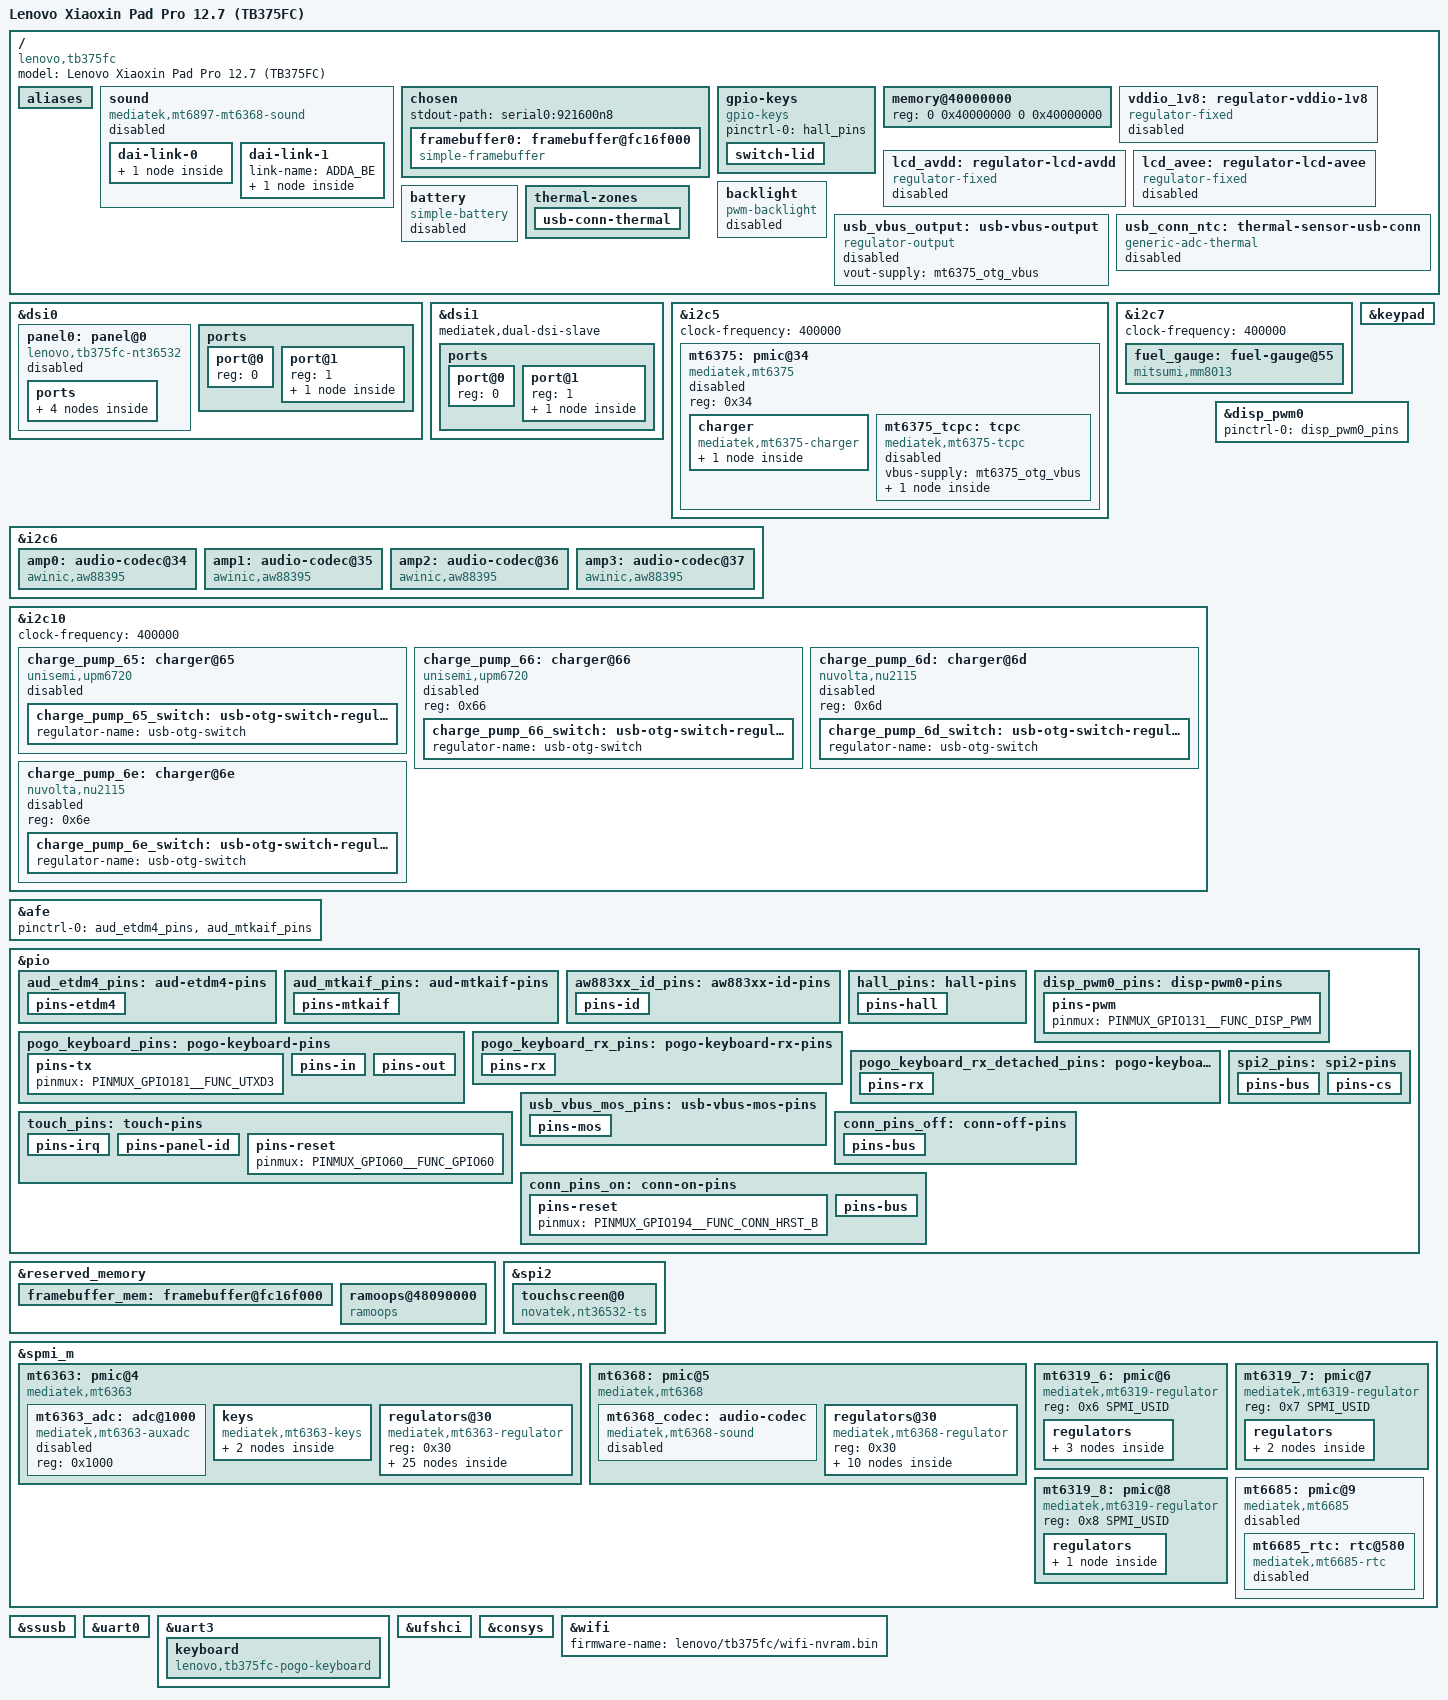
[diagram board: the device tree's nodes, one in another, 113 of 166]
// SPDX-License-Identifier: (GPL-2.0-only OR BSD-2-Clause)
/*
 * Lenovo Xiaoxin Pad Pro 12.7 (2025, TB375FC)
 *
 * Copyright (c) 2026 buntOS contributors
 */

/dts-v1/;
#include <dt-bindings/gpio/gpio.h>
#include <dt-bindings/iio/adc/mediatek,mt6363-auxadc.h>
#include <dt-bindings/input/gpio-keys.h>
#include <dt-bindings/input/input.h>
#include <dt-bindings/interrupt-controller/irq.h>
#include <dt-bindings/spmi/spmi.h>
#include <dt-bindings/usb/pd.h>
#include "mt6897.dtsi"
#include "mt6897-pinfunc.h"

/ {
	model = "Lenovo Xiaoxin Pad Pro 12.7 (TB375FC)";
	compatible = "lenovo,tb375fc", "mediatek,mt6897";

	aliases {
		i2c5 = &i2c5;
		i2c10 = &i2c10;
		serial0 = &uart0;
		spmi0 = &spmi_m;
	};

	sound: sound {
		compatible = "mediatek,mt6897-mt6368-sound";
		model = "TB375FC";
		mediatek,platform = <&afe>;
		audio-routing =
			"Speakers", "Amp0 DAC Output",
			"Speakers", "Amp1 DAC Output",
			"Speakers", "Amp2 DAC Output",
			"Speakers", "Amp3 DAC Output";
		status = "disabled";

		dai-link-0 {
			link-name = "I2SOUT4_BE";
			dai-format = "dsp_b";
			mediatek,clk-provider = "cpu";

			codec {
				sound-dai = <&amp0>, <&amp1>, <&amp2>, <&amp3>;
			};
		};

		dai-link-1 {
			link-name = "ADDA_BE";

			codec {
				sound-dai = <&mt6368_codec>;
			};
		};
	};

	chosen {
		#address-cells = <2>;
		#size-cells = <2>;
		ranges;

		stdout-path = "serial0:921600n8";

		/*
		 * The bootloader drives the panel over both DSI links with DSC
		 * and scans out one 2944x1840 buffer. The base is the one in the
		 * tree it passes to the vendor kernel (atag,videolfb). The stride
		 * and format are from the community port.
		 */
		framebuffer0: framebuffer@fc16f000 {
			compatible = "simple-framebuffer";
			reg = <0 0xfc16f000 0 (2944 * 1840 * 4)>;
			width = <2944>;
			height = <1840>;
			stride = <(2944 * 4)>;
			format = "a8r8g8b8";
			panel = <&panel0>;
		};
	};

	/*
	 * Hall sensor. GPIO1 (stock hall_1) goes low when the cover closes
	 * over the screen. The stock hall_2 is the keyboard's plug-gpios, under
	 * &uart3. The tablet has no sensor for the keyboard folded back: the
	 * keyboard reports that itself, and its driver turns it into
	 * SW_TABLET_MODE.
	 * Checked on the device: low while a cover is closed. Only opening
	 * wakes the tablet: closing a cover over a sleeping tablet woke it,
	 * and logind ignores the lid for a while after a wakeup, so the
	 * screen stayed on under the cover.
	 */
	gpio-keys {
		compatible = "gpio-keys";
		pinctrl-names = "default";
		pinctrl-0 = <&hall_pins>;

		switch-lid {
			label = "Lid";
			gpios = <&pio 1 GPIO_ACTIVE_LOW>;
			linux,input-type = <EV_SW>;
			linux,code = <SW_LID>;
			debounce-interval = <100>;
			wakeup-source;
			wakeup-event-action = <EV_ACT_DEASSERTED>;
		};
	};

	memory@40000000 {
		device_type = "memory";
		/* The bootloader fills in the real size (8 or 12 GiB) */
		reg = <0 0x40000000 0 0x40000000>;
	};

	/*
	 * The panel's 1.8 V I/O supply behind a switch on GPIO63 (stock
	 * vddio_1v8-gpios), which the touch side of the NT36532 shares. The
	 * bootloader turns it on with the panel, and nothing may turn it off
	 * while the display runs on simple-framebuffer. It stays on with the panel
	 * driver: stock turns it on before the DSI links and off after them, which
	 * the driver cannot do, and turns it on before it reads the panel ID strap.
	 * TODO(2c): enable with pio.
	 */
	vddio_1v8: regulator-vddio-1v8 {
		compatible = "regulator-fixed";
		regulator-name = "vddio_1v8";
		regulator-min-microvolt = <1800000>;
		regulator-max-microvolt = <1800000>;
		gpio = <&pio 63 GPIO_ACTIVE_HIGH>;
		enable-active-high;
		regulator-boot-on;
		regulator-always-on;
		status = "disabled";
	};

	/*
	 * The enables of the panel's bias chip, an SM5109 at 0x3e on i2c13 (stock
	 * bias_p-gpios and bias_n-gpios). The bootloader turns them on and writes
	 * 0x12 to its two voltage registers, and the stock kernel does too. Stock
	 * also waits 80 ms after the panel goes off. The chip does not keep the
	 * voltages while off: it reads 0x0e after the panel comes back. TODO: write
	 * them again at every power on. 5.8 V is the value by the formula of the
	 * TPS65132, which has the same two registers; the SM5109's is not known.
	 */
	lcd_avdd: regulator-lcd-avdd {
		compatible = "regulator-fixed";
		regulator-name = "lcd_avdd";
		regulator-min-microvolt = <5800000>;
		regulator-max-microvolt = <5800000>;
		gpio = <&pio 187 GPIO_ACTIVE_HIGH>;
		enable-active-high;
		regulator-boot-on;
		off-on-delay-us = <80000>;
		status = "disabled";
	};

	lcd_avee: regulator-lcd-avee {
		compatible = "regulator-fixed";
		regulator-name = "lcd_avee";
		regulator-min-microvolt = <5800000>;
		regulator-max-microvolt = <5800000>;
		gpio = <&pio 186 GPIO_ACTIVE_HIGH>;
		enable-active-high;
		regulator-boot-on;
		off-on-delay-us = <80000>;
		status = "disabled";
	};

	/*
	 * The display PWM of the SoC sets the brightness, as in the stock tree
	 * (mtk-leds, led-mode 5) and the bootloader's log. Its one output dims the
	 * two SGM37604A LED drivers together, at 0x36 on i2c13 and i2c3. The panel
	 * does nothing with DCS 0x51. The bootloader sets up both LED drivers:
	 * current = I2C code x PWM, with their ramp on, and code 0xdb6, which makes
	 * 21.4 mA per string at full duty. They keep it, so they need no driver.
	 *
	 * The period is the one of the stock tree and of the bootloader, which runs
	 * the PWM at 104 MHz. The LED drivers take 20 to 100 kHz. The levels are
	 * percent of lightness by CIE 1931, as in the default table of pwm-backlight.
	 * Level 1 is about the stock minimum of 4, and the default about the
	 * bootloader's 1945.
	 */
	backlight: backlight {
		compatible = "pwm-backlight";
		pwms = <&disp_pwm0 0 39380>;
		brightness-levels = <0 5 9 14 18 23 27 32 36 41
				     46 52 58 64 71 78 86 94 103 112
				     122 133 144 156 168 181 194 209 223 239
				     255 272 290 309 328 348 369 391 413 436
				     461 486 512 539 567 595 625 656 688 720
				     754 789 825 862 900 939 979 1021 1063 1107
				     1152 1198 1245 1293 1343 1394 1447 1500 1555 1611
				     1669 1728 1788 1849 1913 1977 2043 2110 2179 2249
				     2321 2394 2469 2546 2623 2703 2784 2867 2951 3037
				     3125 3214 3305 3397 3492 3588 3686 3785 3887 3990
				     4095>;
		default-brightness-level = <75>;
		status = "disabled";
	};

	/*
	 * Charging through the MT6375, with the values of the stock tree: ieoc,
	 * min-charge-temp, max-charge-temp, and a charge current of 3 A
	 * (sc-charger-current, and what stock takes from a 3 A Type-C current or a
	 * 5 V PD contract). The voltage is the lowest of its battery maintenance
	 * table, which a battery of any age can take (maintenance-v20-level0-cv,
	 * maintenance-v10-level3-cv), not the 4.5 V of battery-cv. Stock has no
	 * over-voltage threshold of its own, so that one is the next step up in the
	 * fuel gauge's column of that table (maintenance-v10-level2-fg-cv). The
	 * charge pump charges faster with the direct_charge parameter of the charger
	 * driver, which is off by default.
	 */
	battery: battery {
		compatible = "simple-battery";
		constant-charge-voltage-max-microvolt = <4340000>;
		constant-charge-current-max-microamp = <3000000>;
		charge-term-current-microamp = <350000>;
		over-voltage-threshold-microvolt = <4410000>;
		operating-range-celsius = <0 50>;
		status = "disabled";
	};

	/*
	 * Turns the USB VBUS boost on and off from user space, through the state
	 * attribute of this device, until the TCPC driver takes that over. Stays
	 * off with the MT6375 (see &i2c5).
	 */
	usb_vbus_output: usb-vbus-output {
		compatible = "regulator-output";
		vout-supply = <&mt6375_otg_vbus>;
		status = "disabled";
	};

	/*
	 * The NTC at the USB connector, on VIN4 of the MT6363 with its 100 kOhm
	 * pull-up (stock usb_board_ntc on vin4-100k). The resistances are the
	 * ones of the stock table. The AUXADC driver hands out the reading times
	 * its full scale, so a value here is 32768 * R / (R + 100000) * 1840.
	 * Steps of one degree also keep the interpolation in the driver in range.
	 */
	usb_conn_ntc: thermal-sensor-usb-conn {
		compatible = "generic-adc-thermal";
		#thermal-sensor-cells = <0>;
		io-channels = <&mt6363_adc MT6363_AUXADC_VIN4>;
		io-channel-names = "sensor-channel";
		temperature-lookup-table = <
			(-40000) 58951760
			(-39000) 58854240
			(-38000) 58751200
			(-37000) 58640800
			(-36000) 58524880
			(-35000) 58401600
			(-34000) 58270960
			(-33000) 58132960
			(-32000) 57985760
			(-31000) 57831200
			(-30000) 57667440
			(-29000) 57494480
			(-28000) 57312320
			(-27000) 57120960
			(-26000) 56920400
			(-25000) 56706960
			(-24000) 56484320
			(-23000) 56248800
			(-22000) 56002240
			(-21000) 55742800
			(-20000) 55472320
			(-19000) 55188960
			(-18000) 54892720
			(-17000) 54583600
			(-16000) 54259760
			(-15000) 53923040
			(-14000) 53571600
			(-13000) 53205440
			(-12000) 52826400
			(-11000) 52430800
			(-10000) 52022320
			(-9000) 51595440
			(-8000) 51155680
			(-7000) 50701200
			(-6000) 50230160
			(-5000) 49744400
			(-4000) 49245760
			(-3000) 48730560
			(-2000) 48200640
			(-1000) 47657840
			0 47098480
			1000 46526240
			2000 45941120
			3000 45341280
			4000 44730400
			5000 44106640
			6000 43470000
			7000 42824160
			8000 42167280
			9000 41501200
			10000 40824080
			11000 40139600
			12000 39449600
			13000 38750400
			14000 38045680
			15000 37337280
			16000 36621520
			17000 35905760
			18000 35184480
			19000 34463200
			20000 33740080
			21000 33018800
			22000 32297520
			23000 31576240
			24000 30860480
			25000 30146560
			26000 29436320
			27000 28729760
			28000 28030560
			29000 27336880
			30000 26650560
			31000 25971600
			32000 25300000
			33000 24637600
			34000 23984400
			35000 23340400
			36000 22705600
			37000 22083680
			38000 21470960
			39000 20867440
			40000 20276800
			41000 19699040
			42000 19132320
			43000 18576640
			44000 18033840
			45000 17502080
			46000 16981360
			47000 16475360
			48000 15980400
			49000 15496480
			50000 15025440
			51000 14567280
			52000 14120160
			53000 13685920
			54000 13262720
			55000 12850560
			56000 12451280
			57000 12063040
			58000 11685840
			59000 11317840
			60000 10962720
			61000 10616800
			62000 10281920
			63000 9956240
			64000 9641600
			65000 9336160
			66000 9039920
			67000 8752880
			68000 8476880
			69000 8206400
			70000 7946960
			71000 7694880
			72000 7450160
			73000 7212800
			74000 6984640
			75000 6762000
			76000 6548560
			77000 6340640
			78000 6141920
			79000 5946880
			80000 5761040
			81000 5578880
			82000 5404080
			83000 5234800
			84000 5071040
			85000 4912800
			86000 4760080
			87000 4611040
			88000 4467520
			89000 4329520
			90000 4195200
			91000 4066400
			92000 3941280
			93000 3821680
			94000 3703920
			95000 3591680
			96000 3483120
			97000 3376400
			98000 3273360
			99000 3175840
			100000 3080160
			101000 2986320
			102000 2898000
			103000 2811520
			104000 2728720
			105000 2647760
			106000 2568640
			107000 2493200
			108000 2419600
			109000 2349680
			110000 2281600
			111000 2215360
			112000 2150960
			113000 2088400
			114000 2029520
			115000 1970640
			116000 1913600
			117000 1860240
			118000 1808720
			119000 1757200
			120000 1707520
			121000 1659680
			122000 1613680
			123000 1567680
			124000 1525360
			125000 1483040
		>;
		status = "disabled";
	};

	thermal-zones {
		/* The charger reads this one, at its own pace */
		usb-conn-thermal {
			polling-delay = <0>;
			polling-delay-passive = <0>;
			thermal-sensors = <&usb_conn_ntc>;
		};
	};
};

/*
 * The tablet ships with one of three panels. The driver tells BOE from Tianma
 * by the strap on GPIO184, which the touchscreen reads as well; the two Tianma
 * panels take the same init sequence.
 *
 * The stock bootloader does not need these nodes to turn the display on, it has
 * its own device tree for that. On the way to the kernel it looks for
 * /soc/dsi/panel<n>/port/endpoint and logs a failure when it is not there.
 *
 * TODO(2c display): enable with the display pipeline, and take the panel
 * property off framebuffer0 at the same time: fw_devlink would hold simpledrm
 * back until the panel binds. Until then the display runs on simple-framebuffer.
 * The two links make one panel: dsi1 only follows dsi0.
 */
&dsi0 {
	panel0: panel@0 {
		compatible = "lenovo,tb375fc-nt36532", "novatek,nt36532";
		reg = <0>;
		width-mm = <273>;
		height-mm = <171>;
		reset-gpios = <&pio 41 GPIO_ACTIVE_LOW>;
		novatek,panel-id-gpios = <&pio 184 GPIO_ACTIVE_HIGH>;
		vddio-supply = <&vddio_1v8>;
		avdd-supply = <&lcd_avdd>;
		avee-supply = <&lcd_avee>;
		backlight = <&backlight>;
		status = "disabled";

		ports {
			#address-cells = <1>;
			#size-cells = <0>;

			port@0 {
				reg = <0>;

				panel_in0: endpoint {
					remote-endpoint = <&dsi0_out>;
				};
			};

			port@1 {
				reg = <1>;

				panel_in1: endpoint {
					remote-endpoint = <&dsi1_out>;
				};
			};
		};
	};

	ports {
		#address-cells = <1>;
		#size-cells = <0>;

		port@0 {
			reg = <0>;
		};

		port@1 {
			reg = <1>;

			dsi0_out: endpoint {
				remote-endpoint = <&panel_in0>;
			};
		};
	};
};

&dsi1 {
	mediatek,dual-dsi-slave;

	ports {
		#address-cells = <1>;
		#size-cells = <0>;

		port@0 {
			reg = <0>;
		};

		port@1 {
			reg = <1>;

			dsi1_out: endpoint {
				remote-endpoint = <&panel_in1>;
			};
		};
	};
};

/*
 * The MT6375 sources VBUS for USB host mode. Its boost feeds the connector
 * through the input FETs of the charge pump below, which stock closes first.
 *
 * TODO(USB host): stays off with &usb_vbus_output, &i2c5, &i2c10 and
 * &imp_iic_wrap_n/en until UFS root and the USB gadget work on the device. It
 * also needs &pio for its GPIO179 state. The stock tree has no pins and no pull
 * setting for these buses, and runs them at 1 MHz. Check with i2cdetect first,
 * reading only.
 *
 * TODO(charging): with this node alone the driver only reads and charging stays
 * as the bootloader set it. Add monitored-battery = <&battery> and
 * mediatek,fuel-gauge to the charger for it to take over, once the gauge works.
 *
 * TODO(TCPC): add interrupt-parent = <&pio> and interrupts = <7 IRQ_TYPE_LEVEL_LOW>
 * here, which masks all interrupts of the chip at probe, and enable &mt6375_tcpc.
 * First as below, then with power-role and data-role dual (and try-power-role
 * sink), mediatek,usb-port in the charger, &usb_vbus_output off and the port of
 * &ssusb. The order is in the bring-up checklist.
 */
&i2c5 {
	clock-frequency = <400000>;

	mt6375: pmic@34 {
		compatible = "mediatek,mt6375";
		reg = <0x34>;
		status = "disabled";

		charger {
			compatible = "mediatek,mt6375-charger";
			pinctrl-names = "default";
			pinctrl-0 = <&usb_vbus_mos_pins>;
			mediatek,charge-pump = <&charge_pump_65>;

			mt6375_otg_vbus: usb-otg-vbus-regulator {
				regulator-name = "usb-otg-vbus";
				regulator-min-microvolt = <5000000>;
				regulator-max-microvolt = <5000000>;
				vbus-switch-supply = <&charge_pump_65_switch>;
			};
		};

		/*
		 * The fixed contracts that stock takes through the MT6375: 5 V 3 A and
		 * 9 V 2 A. The 9 V line needs the limits that the charge pump driver
		 * writes at probe, as the chip resets to an input over-voltage of 6.5 V,
		 * so that driver loads before this one. op-sink-microwatt stays low as
		 * TCPM cannot ask a PPS source for less. A hard reset, from the source
		 * or after a failed negotiation, takes VBUS away from the USB gadget.
		 * USB 3 may not work until there is a driver for the PS5170 redriver,
		 * which stock sets up by the orientation that the TCPC reports.
		 */
		mt6375_tcpc: tcpc {
			compatible = "mediatek,mt6375-tcpc";
			vbus-supply = <&mt6375_otg_vbus>;
			status = "disabled";

			connector {
				compatible = "usb-c-connector";
				label = "USB-C";
				data-role = "device";
				power-role = "sink";
				sink-pdos = <PDO_FIXED(5000, 3000, PDO_FIXED_USB_COMM)
					     PDO_FIXED(9000, 2000, 0)>;
				op-sink-microwatt = <2500000>;
			};
		};
	};
};

/*
 * The stock tree lists all of these and its drivers bind what answers: NU2115 at
 * 0x6d and 0x6e, or UPM6720 at 0x65 and 0x66. The one that stock names
 * primary_dvchg closes the FETs: the master at 0x6d or 0x65, or a chip strapped
 * as standalone. On the one tablet read so far, stock binds only the UPM6720 at
 * 0x65, so vbus-switch-supply above points at it. Other units may differ.
 *
 * TODO(USB host): on the device, see with i2cdetect which ones answer and which
 * is not strapped as a slave, and enable that one only.
 */
/*
 * The four speakers' smart amplifiers, AW88394 by their stock tuning files. Each
 * takes one slot of the TDM link, which the file picks by audio-channel. The
 * GPIO82 strap tells who made the speakers, and the bus holds its pull-up so
 * that the strap reads true for whichever amplifier probes first. The driver
 * holds a reset line at 0 to reset the chip, so the lines are active high here.
 */
&i2c6 {
	clock-frequency = <400000>;
	pinctrl-names = "default";
	pinctrl-0 = <&aw883xx_id_pins>;

	amp0: audio-codec@34 {
		compatible = "awinic,aw88395";
		reg = <0x34>;
		#sound-dai-cells = <0>;
		reset-gpios = <&pio 78 GPIO_ACTIVE_HIGH>;
		firmware-name = "lenovo/tb375fc/aw883xx_acf_gyt.bin",
				"lenovo/tb375fc/aw883xx_acf_yc.bin";
		awinic,calibration-required;
		awinic,speaker-id-gpios = <&pio 82 GPIO_ACTIVE_HIGH>;
		awinic,audio-channel = <0>;
		sound-name-prefix = "Amp0";
	};

	amp1: audio-codec@35 {
		compatible = "awinic,aw88395";
		reg = <0x35>;
		#sound-dai-cells = <0>;
		reset-gpios = <&pio 79 GPIO_ACTIVE_HIGH>;
		firmware-name = "lenovo/tb375fc/aw883xx_acf_gyt.bin",
				"lenovo/tb375fc/aw883xx_acf_yc.bin";
		awinic,calibration-required;
		awinic,speaker-id-gpios = <&pio 82 GPIO_ACTIVE_HIGH>;
		awinic,audio-channel = <1>;
		sound-name-prefix = "Amp1";
	};

	amp2: audio-codec@36 {
		compatible = "awinic,aw88395";
		reg = <0x36>;
		#sound-dai-cells = <0>;
		reset-gpios = <&pio 80 GPIO_ACTIVE_HIGH>;
		firmware-name = "lenovo/tb375fc/aw883xx_acf_gyt.bin",
				"lenovo/tb375fc/aw883xx_acf_yc.bin";
		awinic,calibration-required;
		awinic,speaker-id-gpios = <&pio 82 GPIO_ACTIVE_HIGH>;
		awinic,audio-channel = <2>;
		sound-name-prefix = "Amp2";
	};

	amp3: audio-codec@37 {
		compatible = "awinic,aw88395";
		reg = <0x37>;
		#sound-dai-cells = <0>;
		reset-gpios = <&pio 81 GPIO_ACTIVE_HIGH>;
		firmware-name = "lenovo/tb375fc/aw883xx_acf_gyt.bin",
				"lenovo/tb375fc/aw883xx_acf_yc.bin";
		awinic,calibration-required;
		awinic,speaker-id-gpios = <&pio 82 GPIO_ACTIVE_HIGH>;
		awinic,audio-channel = <3>;
		sound-name-prefix = "Amp3";
	};
};

&i2c7 {
	clock-frequency = <400000>;

	fuel_gauge: fuel-gauge@55 {
		compatible = "mitsumi,mm8013";
		reg = <0x55>;
		/*
		 * The charger stops at the 4.34 V of &battery, not at the 4.5 V
		 * of stock that the model in the gauge presumably goes up to.
		 * The one full charge watched ended at 89 %, and it read 90 %
		 * hours later on the charger. One under the lower reading, so
		 * that a charge ending a little lower still reads 100 %.
		 */
		mitsumi,charged-soc-percent = <88>;
	};
};

&i2c10 {
	clock-frequency = <400000>;

	charge_pump_65: charger@65 {
		compatible = "unisemi,upm6720";
		reg = <0x65>;
		unisemi,usb-port = <&mt6375_tcpc>;
		unisemi,fuel-gauge = <&fuel_gauge>;
		status = "disabled";

		charge_pump_65_switch: usb-otg-switch-regulator {
			regulator-name = "usb-otg-switch";
		};
	};

	charge_pump_66: charger@66 {
		compatible = "unisemi,upm6720";
		reg = <0x66>;
		status = "disabled";

		charge_pump_66_switch: usb-otg-switch-regulator {
			regulator-name = "usb-otg-switch";
		};
	};

	charge_pump_6d: charger@6d {
		compatible = "nuvolta,nu2115";
		reg = <0x6d>;
		status = "disabled";

		charge_pump_6d_switch: usb-otg-switch-regulator {
			regulator-name = "usb-otg-switch";
		};
	};

	charge_pump_6e: charger@6e {
		compatible = "nuvolta,nu2115";
		reg = <0x6e>;
		status = "disabled";

		charge_pump_6e_switch: usb-otg-switch-regulator {
			regulator-name = "usb-otg-switch";
		};
	};
};

&keypad {
	/* The stock tree maps key 0 to volume down and debounces for 1024 ticks */
	keypad,num-rows = <1>;
	keypad,num-columns = <1>;
	linux,keymap = <MATRIX_KEY(0, 0, KEY_VOLUMEDOWN)>;
	debounce-delay-ms = <32>;
};

&disp_pwm0 {
	pinctrl-names = "default";
	pinctrl-0 = <&disp_pwm0_pins>;
};

&afe {
	pinctrl-names = "default";
	pinctrl-0 = <&aud_etdm4_pins>, <&aud_mtkaif_pins>;
};

&pio {
	aud_etdm4_pins: aud-etdm4-pins {
		pins-etdm4 {
			pinmux = <PINMUX_GPIO65__FUNC_I2SIN4_BCK>,
				 <PINMUX_GPIO4__FUNC_I2SIN4_LRCK>,
				 <PINMUX_GPIO5__FUNC_I2SIN4_DATA0>,
				 <PINMUX_GPIO62__FUNC_I2SOUT4_DATA0>;
			drive-strength = <6>;
			input-schmitt-enable;
			bias-disable;
		};
	};

	aud_mtkaif_pins: aud-mtkaif-pins {
		pins-mtkaif {
			pinmux = <PINMUX_GPIO222__FUNC_AUD_CLK_MOSI>,
				 <PINMUX_GPIO223__FUNC_AUD_SYNC_MOSI>,
				 <PINMUX_GPIO224__FUNC_AUD_DAT_MOSI0>,
				 <PINMUX_GPIO225__FUNC_AUD_DAT_MOSI1>,
				 <PINMUX_GPIO229__FUNC_AUD_DAT_MISO0>,
				 <PINMUX_GPIO230__FUNC_AUD_DAT_MISO1>,
				 <PINMUX_GPIO231__FUNC_AUD_DAT_MISO2>;
			input-schmitt-enable;
			bias-disable;
		};
	};

	aw883xx_id_pins: aw883xx-id-pins {
		pins-id {
			pinmux = <PINMUX_GPIO82__FUNC_GPIO82>;
			input-enable;
			bias-pull-up = <MTK_PUPD_SET_R1R0_10>;
		};
	};

	hall_pins: hall-pins {
		pins-hall {
			pinmux = <PINMUX_GPIO1__FUNC_GPIO1>;
			input-enable;
		};
	};

	disp_pwm0_pins: disp-pwm0-pins {
		pins-pwm {
			pinmux = <PINMUX_GPIO131__FUNC_DISP_PWM>;
		};
	};

	/*
	 * The keyboard cover has one data wire on its pogo pins. UART3 TX drives
	 * it through a gate on GPIO71, and UART3 RX and GPIO40 listen to it.
	 * The stock driver leaves TX on the UART and bias on GPIO26 and GPIO40
	 * as the bootloader set it.
	 */
	pogo_keyboard_pins: pogo-keyboard-pins {
		pins-tx {
			pinmux = <PINMUX_GPIO181__FUNC_UTXD3>;
		};

		pins-in {
			pinmux = <PINMUX_GPIO26__FUNC_GPIO26>,
				 <PINMUX_GPIO40__FUNC_GPIO40>;
			input-enable;
		};

		pins-out {
			pinmux = <PINMUX_GPIO61__FUNC_GPIO61>,
				 <PINMUX_GPIO71__FUNC_GPIO71>;
		};
	};

	pogo_keyboard_rx_pins: pogo-keyboard-rx-pins {
		pins-rx {
			pinmux = <PINMUX_GPIO180__FUNC_URXD3>;
			input-enable;
		};
	};

	/* Nothing drives the wire without a keyboard, so RX leaves the UART */
	pogo_keyboard_rx_detached_pins: pogo-keyboard-rx-detached-pins {
		pins-rx {
			pinmux = <PINMUX_GPIO180__FUNC_GPIO180>;
			input-enable;
			bias-disable;
		};
	};

	/* The stock tree sets drive strength 2, which is 6 mA */
	spi2_pins: spi2-pins {
		pins-bus {
			pinmux = <PINMUX_GPIO11__FUNC_SPI2_CLK>,
				 <PINMUX_GPIO13__FUNC_SPI2_MI>,
				 <PINMUX_GPIO14__FUNC_SPI2_MO>;
			drive-strength = <6>;
		};

		pins-cs {
			pinmux = <PINMUX_GPIO12__FUNC_GPIO12>;
			drive-strength = <6>;
		};
	};

	touch_pins: touch-pins {
		pins-irq {
			pinmux = <PINMUX_GPIO9__FUNC_GPIO9>;
			input-enable;
		};

		pins-panel-id {
			pinmux = <PINMUX_GPIO184__FUNC_GPIO184>;
			input-enable;
		};

		pins-reset {
			pinmux = <PINMUX_GPIO60__FUNC_GPIO60>;
		};
	};

	/*
	 * GPIO179 (stock vbus_mos_gpio) is the over-temperature protection of USB
	 * VBUS. Stock drives it low from its charger probe on and, with a charger
	 * attached, raises it above 75 degrees on the usb_board_ntc sensor.
	 */
	usb_vbus_mos_pins: usb-vbus-mos-pins {
		pins-mos {
			pinmux = <PINMUX_GPIO179__FUNC_GPIO179>;
			output-low;
		};
	};

	/*
	 * The interface of the RF chip. The driver also switches the pull of
	 * GPIO193 and GPIO202, which the stock kernel does without touching
	 * their pull resistor selection.
	 */
	conn_pins_off: conn-off-pins {
		pins-bus {
			pinmux = <PINMUX_GPIO192__FUNC_GPIO192>,
				 <PINMUX_GPIO193__FUNC_GPIO193>,
				 <PINMUX_GPIO194__FUNC_GPIO194>,
				 <PINMUX_GPIO195__FUNC_GPIO195>,
				 <PINMUX_GPIO196__FUNC_GPIO196>,
				 <PINMUX_GPIO197__FUNC_GPIO197>,
				 <PINMUX_GPIO198__FUNC_GPIO198>,
				 <PINMUX_GPIO199__FUNC_GPIO199>,
				 <PINMUX_GPIO200__FUNC_GPIO200>,
				 <PINMUX_GPIO201__FUNC_GPIO201>,
				 <PINMUX_GPIO202__FUNC_GPIO202>;
		};
	};

	conn_pins_on: conn-on-pins {
		pins-reset {
			pinmux = <PINMUX_GPIO194__FUNC_CONN_HRST_B>;
		};

		pins-bus {
			pinmux = <PINMUX_GPIO192__FUNC_CONN_TOP_CLK>,
				 <PINMUX_GPIO193__FUNC_CONN_TOP_DATA>,
				 <PINMUX_GPIO195__FUNC_CONN_WF_CTRL0>,
				 <PINMUX_GPIO196__FUNC_CONN_WF_CTRL1>,
				 <PINMUX_GPIO197__FUNC_CONN_WF_CTRL2>,
				 <PINMUX_GPIO198__FUNC_CONN_WF_CTRL3>,
				 <PINMUX_GPIO199__FUNC_CONN_WF_CTRL4>,
				 <PINMUX_GPIO200__FUNC_CONN_WB_PTA>,
				 <PINMUX_GPIO201__FUNC_CONN_BT_CLK>,
				 <PINMUX_GPIO202__FUNC_CONN_BT_DATA>;
			drive-strength = <4>;
		};
	};
};

&reserved_memory {
	/*
	 * The bootloader's three-buffer allocation behind framebuffer0. It adds
	 * a node of its own for this memory, without no-map, but simpledrm can't
	 * map memory that is in the linear map.
	 */
	framebuffer_mem: framebuffer@fc16f000 {
		reg = <0 0xfc16f000 0 0x3e90000>;
		no-map;
	};

	/*
	 * The bootloader reserves this too (mblock-2-pstore) and passes the same
	 * values as ramoops.* on the command line. Those win and this device
	 * then fails to probe with "already initialized". It is here for boots
	 * without them. The sizes are the vendor kernel's, so that the slot with
	 * Android finds the records in the same places.
	 */
	ramoops@48090000 {
		compatible = "ramoops";
		reg = <0 0x48090000 0 0xe0000>;
		record-size = <0x1000>;
		console-size = <0x40000>;
		ftrace-size = <0x1000>;
		pmsg-size = <0x80000>;
	};
};

/* TODO(2c): spi2 stays disabled (mt6897.dtsi) until pio and the clocks are on */
&spi2 {
	pinctrl-names = "default";
	pinctrl-0 = <&spi2_pins>;
	/*
	 * Through the controller's own chip select the NT36532 only reads back
	 * zeros. The same transfers answer with the trim ID when GPIO12 is
	 * driven by software, at every speed tried up to 4 MHz.
	 */
	cs-gpios = <&pio 12 GPIO_ACTIVE_LOW>;

	/*
	 * The touch and stylus side of the NT36532 TDDI. The firmware is tuned
	 * per panel: the panel ID strap on GPIO184 reads 0 with the BOE panel
	 * and 1 with the two Tianma panels. The controller's X runs along the
	 * 1840-pixel side and Y along the 2944-pixel side, both in tenths of a
	 * pixel and up to 18400 and 29440, while the panel scans out
	 * 2944x1840. The active area is 273.6 x 171.0 mm (12.7", 16:10).
	 * The controller's X runs against the panel's lines.
	 */
	touchscreen@0 {
		compatible = "novatek,nt36532-ts";
		reg = <0>;
		spi-max-frequency = <9600000>;
		panel = <&panel0>;
		interrupts-extended = <&pio 9 IRQ_TYPE_EDGE_RISING>;
		reset-gpios = <&pio 60 GPIO_ACTIVE_LOW>;
		iovcc-supply = <&vddio_1v8>;
		pinctrl-names = "default";
		pinctrl-0 = <&touch_pins>;
		firmware-name = "lenovo/tb375fc/novatek_ts_fw_boe.bin",
				"lenovo/tb375fc/novatek_ts_fw_tm.bin";
		novatek,panel-id-gpios = <&pio 184 GPIO_ACTIVE_HIGH>;
		touchscreen-size-x = <18401>;
		touchscreen-size-y = <29441>;
		touchscreen-x-mm = <171>;
		touchscreen-y-mm = <273>;
		touchscreen-inverted-x;
		touchscreen-swapped-x-y;
	};
};

&spmi_m {
	/*
	 * MT6363 main PMIC. The key interrupts are those of the stock
	 * driver's PSC group: PWRKEY 48, HOMEKEY 49, PWRKEY_R 51 and
	 * HOMEKEY_R 52. The stock tree uses HOMEKEY as volume up and resets
	 * on a long press of both keys.
	 */
	mt6363: pmic@4 {
		compatible = "mediatek,mt6363";
		reg = <0x4 SPMI_USID>;
		interrupts = <0x4 64 IRQ_TYPE_LEVEL_HIGH>;
		interrupt-controller;
		#interrupt-cells = <3>;
		#address-cells = <1>;
		#size-cells = <0>;

		mt6363_adc: adc@1000 {
			compatible = "mediatek,mt6363-auxadc";
			reg = <0x1000>;
			#io-channel-cells = <1>;
			status = "disabled";
		};

		keys {
			compatible = "mediatek,mt6363-keys";
			mediatek,long-press-mode = <2>;
			power-off-time-sec = <0>;
			/* Press to sleep, hold to power off. Two keys reset. */
			mediatek,power-key-hold-sec = <10>;

			power-key {
				interrupts = <0x4 48 IRQ_TYPE_LEVEL_HIGH>,
					     <0x4 51 IRQ_TYPE_LEVEL_HIGH>;
				interrupt-names = "powerkey", "powerkey_r";
				linux,keycodes = <KEY_POWER>;
				wakeup-source;
			};

			home-key {
				interrupts = <0x4 49 IRQ_TYPE_LEVEL_HIGH>,
					     <0x4 52 IRQ_TYPE_LEVEL_HIGH>;
				interrupt-names = "homekey", "homekey_r";
				linux,keycodes = <KEY_VOLUMEUP>;
			};
		};

		/*
		 * The rails the stock tree keeps on, and VEMC for UFS. The
		 * stock tree turns the others (vbuck1, vbuck3, vbuck7, vcn13,
		 * vcn15, vrf*, vsram-digrf) on for the modem, RF and
		 * connectivity when they need them; leaving them out of this
		 * node keeps Linux from touching them. Nothing sets a voltage
		 * yet, so no limits are given and the core keeps what the
		 * bootloader set. Names come from the stock consumers where
		 * there is one: dvfsrc (vcore), the GPU SRAM, the modem and UFS.
		 */
		regulators@30 {
			compatible = "mediatek,mt6363-regulator";
			reg = <0x30>;

			mt6363_va12_1: va12-1 {
				regulator-name = "mt6363_va12_1";
				regulator-enable-ramp-delay = <180>;
				regulator-always-on;
			};

			mt6363_va12_2: va12-2 {
				regulator-name = "mt6363_va12_2";
				regulator-enable-ramp-delay = <180>;
				regulator-always-on;
			};

			mt6363_va15: va15 {
				regulator-name = "mt6363_va15";
				regulator-enable-ramp-delay = <180>;
				regulator-always-on;
			};

			mt6363_vaux18: vaux18 {
				regulator-name = "mt6363_vaux18";
				regulator-enable-ramp-delay = <240>;
				regulator-always-on;
			};

			mt6363_vbuck2: vbuck2 {
				regulator-name = "vmodem";
				regulator-enable-ramp-delay = <200>;
				regulator-always-on;
			};

			mt6363_vbuck4: vbuck4 {
				regulator-name = "mt6363_vbuck4";
				regulator-enable-ramp-delay = <200>;
				regulator-always-on;
			};

			mt6363_vbuck5: vbuck5 {
				regulator-name = "mt6363_vbuck5";
				regulator-enable-ramp-delay = <200>;
				regulator-always-on;
			};

			mt6363_vbuck6: vbuck6 {
				regulator-name = "vcore";
				regulator-enable-ramp-delay = <300>;
				regulator-always-on;
			};

			/*
			 * Disabled rails stay as they are, like the ones left out
			 * of this node. They wait for the connectivity bring-up.
			 */
			mt6363_vcn13: vcn13 {
				regulator-name = "mt6363_vcn13";
				regulator-min-microvolt = <1350000>;
				regulator-max-microvolt = <1350000>;
				regulator-enable-ramp-delay = <180>;
				regulator-allowed-modes = <0 2>;
				status = "disabled";
			};

			mt6363_vemc: vemc {
				regulator-name = "vufs_vcc";
				regulator-enable-ramp-delay = <680>;
			};

			mt6363_vio0p75: vio0p75 {
				regulator-name = "mt6363_vio0p75";
				regulator-enable-ramp-delay = <3000>;
				regulator-always-on;
			};

			mt6363_vio18: vio18 {
				regulator-name = "vio18";
				regulator-enable-ramp-delay = <680>;
				regulator-always-on;
			};

			mt6363_vm18: vm18 {
				regulator-name = "mt6363_vm18";
				regulator-enable-ramp-delay = <280>;
				regulator-always-on;
			};

			/* Feeds the 1.8 V side of the RF chip, at 1.7 V as the stock driver does */
			mt6363_vrfio18: vrf-io18 {
				regulator-name = "mt6363_vrfio18";
				regulator-min-microvolt = <1700000>;
				regulator-max-microvolt = <1700000>;
				regulator-enable-ramp-delay = <180>;
				regulator-allowed-modes = <0 2>;
				status = "disabled";
			};

			mt6363_vs1: vs1 {
				regulator-name = "mt6363_vs1";
				regulator-enable-ramp-delay = <180>;
				regulator-always-on;
			};

			mt6363_vs2: vs2 {
				regulator-name = "mt6363_vs2";
				regulator-enable-ramp-delay = <180>;
				regulator-always-on;
			};

			mt6363_vs3: vs3 {
				regulator-name = "mt6363_vs3";
				regulator-enable-ramp-delay = <180>;
				regulator-always-on;
			};

			mt6363_vsram_cpub: vsram-cpub {
				regulator-name = "mt6363_vsram_cpub";
				regulator-enable-ramp-delay = <180>;
				regulator-always-on;
			};

			mt6363_vsram_cpul: vsram-cpul {
				regulator-name = "mt6363_vsram_cpul";
				regulator-enable-ramp-delay = <180>;
				regulator-always-on;
			};

			mt6363_vsram_cpum: vsram-cpum {
				regulator-name = "mt6363_vsram_cpum";
				regulator-enable-ramp-delay = <180>;
				regulator-always-on;
			};

			mt6363_vsram_mdfe: vsram-mdfe {
				regulator-name = "vsram_gpu";
				regulator-enable-ramp-delay = <180>;
				regulator-always-on;
			};

			mt6363_vsram_modem: vsram-modem {
				regulator-name = "vsram_modem";
				regulator-enable-ramp-delay = <180>;
				regulator-always-on;
			};

			mt6363_vtref18: vtref18 {
				regulator-name = "mt6363_vtref18";
				regulator-enable-ramp-delay = <240>;
				regulator-always-on;
			};

			mt6363_vufs12: vufs12 {
				regulator-name = "mt6363_vufs12";
				regulator-enable-ramp-delay = <280>;
				regulator-always-on;
			};

			mt6363_vufs18: vufs18 {
				regulator-name = "mt6363_vufs18";
				regulator-enable-ramp-delay = <680>;
				regulator-always-on;
			};
		};
	};

	/*
	 * MT6368 second PMIC, with the rails the stock tree keeps on: among
	 * them USB's analog supply and the GPU core, which stays on until a
	 * GPU driver takes it. The stock tree leaves the others to their
	 * users, such as vibr (the vibrator and the camera autofocus), vfp
	 * (the fingerprint sensor), vmc and vmch-eint-* (the SD card) and
	 * vsim2 (the cameras); leaving them
	 * out of this node keeps Linux from touching them. As on the MT6363,
	 * no voltage limits are given and the names come from the stock
	 * consumers where there is one.
	 */
	mt6368: pmic@5 {
		compatible = "mediatek,mt6368";
		reg = <0x5 SPMI_USID>;
		interrupts = <0x5 48 IRQ_TYPE_LEVEL_HIGH>;
		interrupt-controller;
		#interrupt-cells = <3>;
		#address-cells = <1>;
		#size-cells = <0>;

		/* Three analog microphones with direct coupling, by the stock tree */
		mt6368_codec: audio-codec {
			compatible = "mediatek,mt6368-sound";
			#sound-dai-cells = <0>;
			mediatek,dcxo = <&mt6685>;
			mediatek,mic-type-0 = <3>;
			mediatek,mic-type-1 = <3>;
			mediatek,mic-type-2 = <3>;
			vaud18-supply = <&mt6368_vaud18>;
			status = "disabled";
		};

		regulators@30 {
			compatible = "mediatek,mt6368-regulator";
			reg = <0x30>;

			mt6368_vant18: vant18 {
				regulator-name = "mt6368_vant18";
				regulator-enable-ramp-delay = <680>;
				regulator-allowed-modes = <0 2>;
				status = "disabled";
			};

			mt6368_vaud18: vaud18 {
				regulator-name = "mt6368_vaud18";
				regulator-enable-ramp-delay = <680>;
				regulator-allowed-modes = <0 2>;
				status = "disabled";
			};

			mt6368_vbuck2: vbuck2 {
				regulator-name = "vgpu";
				regulator-enable-ramp-delay = <200>;
				regulator-always-on;
			};

			mt6368_vbuck5: vbuck5 {
				regulator-name = "mt6368_vbuck5";
				regulator-enable-ramp-delay = <180>;
				regulator-always-on;
			};

			mt6368_vbuck6: vbuck6 {
				regulator-name = "mt6368_vbuck6";
				regulator-enable-ramp-delay = <180>;
				regulator-always-on;
			};

			mt6368_vcn33_1: vcn33-1 {
				regulator-name = "mt6368_vcn33_1";
				regulator-enable-ramp-delay = <680>;
				regulator-allowed-modes = <0 2>;
				status = "disabled";
			};

			mt6368_vcn33_2: vcn33-2 {
				regulator-name = "mt6368_vcn33_2";
				regulator-enable-ramp-delay = <680>;
				regulator-allowed-modes = <0 2>;
				status = "disabled";
			};

			mt6368_vio28: vio28 {
				regulator-name = "mt6368_vio28";
				regulator-enable-ramp-delay = <680>;
				regulator-always-on;
			};

			mt6368_vtp: vtp {
				regulator-name = "mt6368_vtp";
				regulator-enable-ramp-delay = <680>;
				regulator-always-on;
			};

			mt6368_vusb: vusb {
				regulator-name = "vusb33";
				regulator-enable-ramp-delay = <680>;
				regulator-always-on;
			};
		};
	};

	/*
	 * MT6319 buck PMICs, as in the stock tree. Their users there:
	 * 6/vbuck1 the ISP and camera power domains, 6/vbuck3 (proc1 and
	 * proc4), 7/vbuck1 (proc2) and 6/vbuck4 (proc3) the CPU DVFS that
	 * the MCUPM drives, 8/vbuck3 UFS VCCQ; 7/vbuck3 has none. Buck 2 is
	 * paired with buck 1 on all three. UFS takes 8/vbuck3 here too, and
	 * nothing claims the others yet, so all of them stay on through the
	 * unused regulator cleanup. The driver picks the paired bucks by SID
	 * as on MT8195 boards, which does not match this board, so no
	 * operating modes are allowed.
	 *
	 * The stock voltage limits are left out: Linux must not change these
	 * bucks, and with limits the regulator core reads the voltage when it
	 * registers them. On 8/vbuck3 that read gives -EINVAL here, which fails
	 * the whole PMIC.
	 */
	mt6319_6: pmic@6 {
		compatible = "mediatek,mt6319-regulator", "mediatek,mt6315-regulator";
		reg = <0x6 SPMI_USID>;

		regulators {
			mt6319_6_vbuck1: vbuck1 {
				regulator-name = "vmm";
				regulator-enable-ramp-delay = <256>;
				regulator-always-on;
			};

			mt6319_6_vbuck3: vbuck3 {
				regulator-name = "vproc1";
				regulator-enable-ramp-delay = <256>;
				regulator-always-on;
			};

			mt6319_6_vbuck4: vbuck4 {
				regulator-name = "vproc3";
				regulator-enable-ramp-delay = <256>;
				regulator-always-on;
			};
		};
	};

	mt6319_7: pmic@7 {
		compatible = "mediatek,mt6319-regulator", "mediatek,mt6315-regulator";
		reg = <0x7 SPMI_USID>;

		regulators {
			mt6319_7_vbuck1: vbuck1 {
				regulator-name = "vproc2";
				regulator-enable-ramp-delay = <256>;
				regulator-always-on;
			};

			mt6319_7_vbuck3: vbuck3 {
				regulator-name = "mt6319_7_vbuck3";
				regulator-enable-ramp-delay = <256>;
				regulator-always-on;
			};
		};
	};

	mt6319_8: pmic@8 {
		compatible = "mediatek,mt6319-regulator", "mediatek,mt6315-regulator";
		reg = <0x8 SPMI_USID>;

		regulators {
			mt6319_8_vbuck3: vbuck3 {
				regulator-name = "vufs_vccq";
				regulator-enable-ramp-delay = <256>;
				regulator-always-on;
			};
		};
	};

	/*
	 * Clock buffer, RTC and more. Nothing here touches the clock buffer. The
	 * MFD driver passes on the one interrupt, that of the RTC, and populates
	 * the children. The connectivity driver reads the frequency of the RF
	 * chip's clock from it.
	 * TODO(2b): enable with the RTC, or with consys in 2d, whichever is first.
	 */
	mt6685: pmic@9 {
		compatible = "mediatek,mt6685";
		reg = <0x9 SPMI_USID>;
		interrupts = <0x9 0 IRQ_TYPE_LEVEL_HIGH>;
		interrupt-controller;
		#interrupt-cells = <3>;
		#address-cells = <1>;
		#size-cells = <0>;
		status = "disabled";

		/*
		 * The alarm wakes the system, as in the stock tree.
		 * TODO(2b): enable to read and set the time. It writes the two clock
		 * gates when reading, and the time when asked to.
		 */
		mt6685_rtc: rtc@580 {
			compatible = "mediatek,mt6685-rtc";
			reg = <0x580>;
			interrupts = <0x9 0 IRQ_TYPE_LEVEL_HIGH>;
			status = "disabled";
		};
	};
};

/*
 * USB's analog supply, as in the stock tree. The stock controller is dual role,
 * but this starts as a USB device only, because the USB gadget is the way into
 * the tablet while it is being brought up.
 *
 * TODO(USB host): once UFS root and the gadget work on the device, and the
 * nodes under &i2c5 and &i2c10 are on, enable &xhci0 and add
 *
 *	dr_mode = "otg";
 *	usb-role-switch;
 *	role-switch-default-mode = "peripheral";
 *
 * The role is then in /sys/class/usb_role/11201000.usb-role-switch/role and VBUS
 * in the state attribute of &usb_vbus_output. Without the TCPC nothing does this
 * by itself. Never add vbus-supply here: in otg mode ssusb_host_setup() enables
 * it at every probe, whatever is on the port.
 *
 * TODO(TCPC): with the TCPC the role comes over a graph between the connector and
 * a port here, and the attributes are not needed. Keep role-switch-default-mode:
 * without it, TCPM's role of none means host to this driver.
 */
&ssusb {
	dr_mode = "peripheral";
	/* USB 3 goes through the PS5170 redriver, which has no driver yet */
	maximum-speed = "high-speed";
	/* VBUS goes to the charger; without this the controller stays off the bus */
	mediatek,force-vbus;
	vusb33-supply = <&mt6368_vusb>;
};

/* Debug UART, GPIO207 (TX) and GPIO208 (RX) */
&uart0 {
	status = "okay";
};

/*
 * TODO(2c): uart3 stays disabled (mt6897.dtsi) until pio and the clock
 * controllers are on. Then check the attach and detach levels of GPIO26, that
 * the first frames decode, and what the keyboard sends when folded back.
 */
&uart3 {
	/*
	 * The keyboard cover. GPIO61 switches its supply, GPIO26 (stock hall_2)
	 * goes low when a keyboard is attached and GPIO40 wakes the system when
	 * a sleeping keyboard starts to send.
	 */
	keyboard {
		compatible = "lenovo,tb375fc-pogo-keyboard";
		power-gpios = <&pio 61 GPIO_ACTIVE_HIGH>;
		tx-enable-gpios = <&pio 71 GPIO_ACTIVE_HIGH>;
		wake-gpios = <&pio 40 GPIO_ACTIVE_HIGH>;
		plug-gpios = <&pio 26 GPIO_ACTIVE_LOW>;
		pinctrl-names = "default", "detached";
		pinctrl-0 = <&pogo_keyboard_pins>, <&pogo_keyboard_rx_pins>;
		pinctrl-1 = <&pogo_keyboard_pins>, <&pogo_keyboard_rx_detached_pins>;
		wakeup-source;
	};
};

/* UFS supplies, as in the stock tree */
&ufshci {
	vcc-supply = <&mt6363_vemc>;
	vccq-supply = <&mt6319_8_vbuck3>;
};

&consys {
	vcn13-supply = <&mt6363_vcn13>;
	vrfio18-supply = <&mt6363_vrfio18>;
	vcn33-1-supply = <&mt6368_vcn33_1>;
	vcn33-2-supply = <&mt6368_vcn33_2>;
	vant18-supply = <&mt6368_vant18>;
	mediatek,dcxo = <&mt6685>;
	pinctrl-names = "default", "active";
	pinctrl-0 = <&conn_pins_off>;
	pinctrl-1 = <&conn_pins_on>;
};

/*
 * The stock tree picks the RF front end by a hardware ID property it does not
 * have, which makes it none, unless a file on the device says otherwise. Leaving
 * out mediatek,fem-parts says none. TODO(2d): compare with the "FemInfo" line of
 * the stock driver's log.
 */
&wifi {
	firmware-name = "lenovo/tb375fc/wifi-nvram.bin";
};
